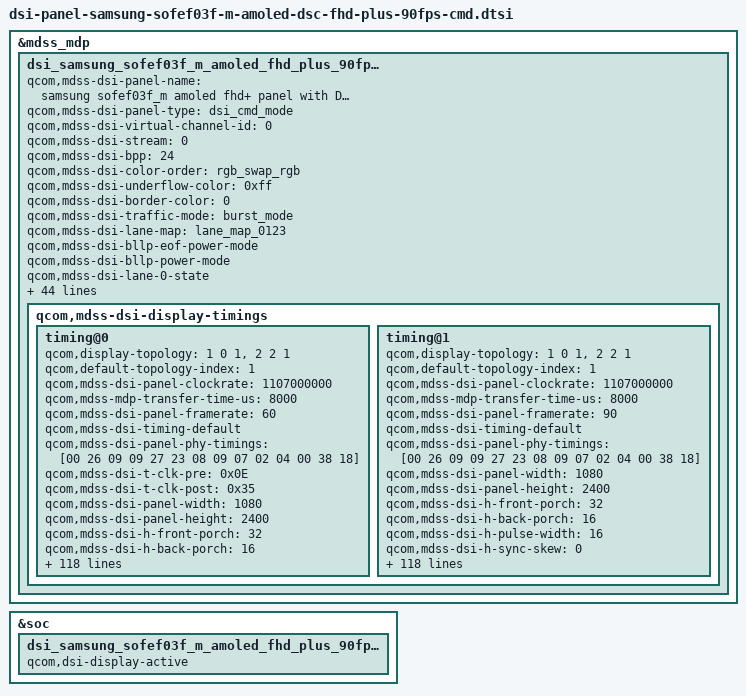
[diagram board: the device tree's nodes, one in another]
/* Copyright (c) 2018, The Linux Foundation. All rights reserved.
 *
 * This program is free software; you can redistribute it and/or modify
 * it under the terms of the GNU General Public License version 2 and
 * only version 2 as published by the Free Software Foundation.
 *
 * This program is distributed in the hope that it will be useful,
 * but WITHOUT ANY WARRANTY; without even the implied warranty of
 * MERCHANTABILITY or FITNESS FOR A PARTICULAR PURPOSE.  See the
 * GNU General Public License for more details.
 */

&mdss_mdp {
	dsi_samsung_sofef03f_m_amoled_fhd_plus_90fps_cmd: qcom,mdss_dsi_samsung_sofef03f_m_fhd_plus_90fps_cmd {
		qcom,mdss-dsi-panel-name =
		  "samsung sofef03f_m amoled fhd+ panel with DSC";
		qcom,mdss-dsi-panel-type = "dsi_cmd_mode";
		qcom,mdss-dsi-virtual-channel-id = <0>;
		qcom,mdss-dsi-stream = <0>;
		qcom,mdss-dsi-bpp = <24>;
		qcom,mdss-dsi-color-order = "rgb_swap_rgb";
		qcom,mdss-dsi-underflow-color = <0xff>;
		qcom,mdss-dsi-border-color = <0>;
		qcom,mdss-dsi-traffic-mode = "burst_mode";
		qcom,mdss-dsi-lane-map = "lane_map_0123";
		qcom,mdss-dsi-bllp-eof-power-mode;
		qcom,mdss-dsi-bllp-power-mode;
		qcom,mdss-dsi-lane-0-state;
		qcom,mdss-dsi-lane-1-state;
		qcom,mdss-dsi-lane-2-state;
		qcom,mdss-dsi-lane-3-state;
		qcom,mdss-dsi-dma-trigger = "trigger_sw";
		qcom,mdss-dsi-mdp-trigger = "trigger_sw";
		qcom,mdss-dsi-reset-sequence = <1 5>, <0 10>, <1 10>;
		//#ifdef OPLUS_BUG_STABILITY
		qcom,mdss-dsi-mode-sel-gpio-state = "single_port";
		oplus,lcd-delay-vci-gpio = <5000>;
		oplus,lcd-delay-disp-en-gpio = <0>;
		oplus,lcd-delay-reset-gpio = <12000>;
		oplus,lcd-delay-mode-sel-gpio = <5000>;
		oplus,lcd-delay-set-pinctrl-state = <1000>;
		oplus,lcd-delay-enable-regulator = <0>;
		oplus,mdss-dsi-vendor-name = "SOFEF03F_M";
		oplus,mdss-dsi-manufacture = "samsung1024";
		//#endif /* OPLUS_BUG_STABILITY */
		qcom,bl-update-flag = "delay_until_first_frame";
		qcom,mdss-dsi-bl-pmic-control-type = "bl_ctrl_dcs";
		qcom,mdss-dsi-bl-min-level = <6>;
		qcom,mdss-dsi-bl-max-level = <2047>;
		qcom,mdss-brightness-default-val = <400>;
		qcom,mdss-brightness-max-level = <2047>;
		qcom,mdss-dsi-bl-normal-max-level = <1023>;
		qcom,mdss-brightness-normal-max-level = <1023>;
		qcom,mdss-dsi-te-pin-select = <1>;
		qcom,mdss-dsi-wr-mem-start = <0x2c>;
		qcom,mdss-dsi-wr-mem-continue = <0x3c>;
		qcom,mdss-dsi-te-dcs-command = <1>;
		qcom,mdss-pan-physical-width-dimension = <68>;
		qcom,mdss-pan-physical-height-dimension = <152>;
		qcom,dynamic-mode-switch-enabled;
		qcom,dynamic-mode-switch-type = "dynamic-switch-immediate";
		qcom,mdss-dsi-panel-hdr-enabled;
		qcom,mdss-dsi-panel-hdr-color-primaries = <15000 15500 34000
			16000 13250 34500 7500 3000>;
		qcom,mdss-dsi-panel-peak-brightness = <4300000>;
		qcom,mdss-dsi-panel-blackness-level = <1023>;
		oplus,dsi-dc-brightness = <0 0xff>,
					<1 0xfb>,
					<2 0xfb>,
					<3 0xfb>,
					<4 0xfa>,
					<5 0xf9>,
					<6 0xf7>,
					<8 0xf5>,
					<10 0xf3>,
					<15 0xf0>,
					<20 0xea>,
					<30 0xe0>,
					<45 0xd0>,
					<70 0xbc>,
					<100 0x98>,
					<120 0x80>,
					<140 0x70>,
					<160 0x58>,
					<180 0x48>,
					<200 0x30>,
					<220 0x20>,
					<240 0x10>,
					<260 0x00>;

		qcom,mdss-dsi-display-timings {
			timing@0{
				qcom,display-topology = <1 0 1>, <2 2 1>;
				qcom,default-topology-index = <1>;
				qcom,mdss-dsi-panel-clockrate = <1107000000>;
				qcom,mdss-mdp-transfer-time-us = <8000>; //for 60fps
				qcom,mdss-dsi-panel-framerate = <60>;
				qcom,mdss-dsi-timing-default;
				qcom,mdss-dsi-panel-phy-timings = [00 26 09 09 27 23 08 09 07 02 04 00 38 18];
				qcom,mdss-dsi-t-clk-pre = <0x0E>;
				qcom,mdss-dsi-t-clk-post = <0x35>;
				qcom,mdss-dsi-panel-width = <1080>;
				qcom,mdss-dsi-panel-height = <2400>;
				qcom,mdss-dsi-h-front-porch = <32>;
				qcom,mdss-dsi-h-back-porch = <16>;
				qcom,mdss-dsi-h-pulse-width = <16>;
				qcom,mdss-dsi-h-sync-skew = <0>;
				qcom,mdss-dsi-h-sync-pulse = <0>;
				qcom,mdss-dsi-v-back-porch = <12>;
				qcom,mdss-dsi-v-front-porch = <12>;
				qcom,mdss-dsi-v-pulse-width = <4>;
				qcom,mdss-dsi-h-left-border = <0>;
				qcom,mdss-dsi-h-right-border = <0>;
				qcom,mdss-dsi-v-top-border = <0>;
				qcom,mdss-dsi-v-bottom-border = <0>;
				qcom,mdss-dsi-panel-jitter = <0x4 0x1>;
				qcom,esd-check-enabled;
				qcom,mdss-dsi-panel-status-check-mode = "reg_read";
				qcom,mdss-dsi-panel-status-command = [06 01 00 01 05 00 02 0A 00];
				qcom,mdss-dsi-panel-status-command-state = "dsi_hs_mode";
				qcom,mdss-dsi-panel-status-value = <0x9C>;
				qcom,mdss-dsi-panel-status-read-length = <1>;
				oplus,fod-on-vblank = <2>;
				oplus,fod-off-vblank = <0>;

				qcom,mdss-dsi-timing-switch-command = [
					/* 60hz Transition */
					39 01 00 00 00 00 03 F0 5A 5A
					15 01 00 00 00 00 02 60 00				/* 0x00 : 60 Hz */
					39 01 00 00 00 00 03 F0 A5 A5
				];
				qcom,mdss-dsi-panel-read-register-open-command = [
					39 01 00 00 00 00 03 F0 5A 5A
				];
				qcom,mdss-dsi-panel-id1-command = [
					06 01 00 00 00 00 02 0A 00
				];
				qcom,mdss-dsi-panel-id2-command = [
					06 01 00 00 00 00 02 B6 00
				];
				qcom,mdss-dsi-panel-read-register-close-command = [
					39 01 00 00 00 00 03 F0 A5 A5
				];
				qcom,mdss-dsi-on-command = [
					/* DSC Setting */
					15 01 00 00 00 00 02 9D 01
					39 01 00 00 00 00 81 9E
					11 00 00 89 30 80 09 60
					04 38 00 1E 02 1C 02 1C
					02 00 02 0E 00 20 02 E3
					00 07 00 0C 03 50 03 64
					18 00 10 F0 03 0C 20 00
					06 0B 0B 33 0E 1C 2A 38
					46 54 62 69 70 77 79 7B
					7D 7E 01 02 01 00 09 40
					09 BE 19 FC 19 FA 19 F8
					1A 38 1A 78 1A B6 2A F6
					2B 34 2B 74 3B 74 6B F4
					00 00 00 00 00 00 00 00
					00 00 00 00 00 00 00 00
					00 00 00 00 00 00 00 00
					00 00 00 00 00 00 00 00
					00 00 00 00 00 00 00 00
					/* Sleep Out(11h) */
					05 01 00 00 0A 00 01 11
					/* Common Setting */
					39 01 00 00 0A 00 03 F0 5A 5A
					15 01 00 00 00 00 02 35 00				/* TE Vsync On */
					39 01 00 00 00 00 03 F0 A5 A5
					/* PAGE ADDRESS SET */
					39 01 00 00 00 00 05 2A 00 00 04 37     /* Page Address Set */
					39 01 00 00 00 00 05 2B 00 00 09 5F		/* Page Address Set */
					/* ELVSS Dim Setting */
					39 01 00 00 00 00 03 F0 5A 5A
					15 01 00 00 00 00 02 B0 05
					15 01 00 00 00 00 02 B7 13				/* 0x13 : ELVSS DIM OFF */
					39 01 00 00 00 00 03 F0 A5 A5
					/* Dimming Delay control */
					39 01 00 00 00 00 03 F0 5A 5A
					15 01 00 00 00 00 02 B0 01
					15 01 00 00 00 00 02 B7 5B				/* 0x53 : DLY OFF */
					39 01 00 00 00 00 03 F0 A5 A5
					/* Dimming Speed Control */
					39 01 00 00 00 00 03 F0 5A 5A
					15 01 00 00 00 00 02 B0 06
					15 01 00 00 00 00 02 B7 01				/* 0x01 : 1 Frames */
					39 01 00 00 00 00 03 F0 A5 A5
					/* FD Setting */
					39 01 00 00 00 00 03 F0 5A 5A
					15 01 00 00 00 00 02 B0 0A
					15 01 00 00 00 00 02 D5 05
					39 01 00 00 00 00 03 F0 A5 A5
					/*  ERR_FG Setting */
					39 01 00 00 00 00 03 F0 5A 5A
					39 01 00 00 00 00 02 B0 02
					39 01 00 00 00 00 05 EC 00 C2 C2 42
					39 01 00 00 00 00 02 B0 0D
					39 01 00 00 00 00 02 EC 19
					39 01 00 00 00 00 03 F0 A5 A5
					/*  Frame Freq Setting +0.5HZ */
					39 01 00 00 00 00 03 FC 5A 5A
					39 01 00 00 00 00 03 F0 5A 5A
					39 01 00 00 00 00 02 B0 17
					39 01 00 00 00 00 02 D1 5D
					39 01 00 00 00 00 02 B0 2A
					39 01 00 00 00 00 06 D3 29 00 00 0D 29
					39 01 00 00 00 00 02 B0 78
					39 01 00 00 00 00 06 D3 4F 00 00 06 4F
					39 01 00 00 00 00 02 B0 AF
					39 01 00 00 00 00 06 D3 29 00 00 0D 29
					39 01 00 00 00 00 02 F7 03
					39 01 00 00 00 00 02 B0 04
					39 01 00 00 00 00 02 D9 72
					39 01 00 00 00 00 03 F0 A5 A5
					39 01 00 00 00 00 03 FC A5 A5
					/* Brightness Control */
					15 01 00 00 00 00 02 53 20				/* 0x20 Normal transition */
					/* ACL Control */
					15 01 00 00 00 00 02 55 00				/* 0x00 Acl off */
					39 01 00 00 00 00 03 51 00 00
					/* 60hz Transition */
					39 01 00 00 00 00 03 F0 5A 5A
					15 01 00 00 00 00 02 60 00				/* 0x00 : 60 Hz */
					39 01 00 00 46 00 03 F0 A5 A5
					/* Display On */
					//05 01 00 00 00 00 01 29
				];
				qcom,mdss-113mhz-osc-dsi-on-command = [
					39 01 00 00 00 00 03 FC 5A 5A
					15 01 00 00 00 00 02 B0 01
					39 01 00 00 00 00 04 E4 A6 75 A3
					39 01 00 00 00 00 0F E9 11 75 A6 75 A3 C7 FB F0 C7 FB F0 00 32 32
					39 01 00 00 00 00 03 FC A5 A5
				];
				qcom,mdss-dsi-post-on-backlight = [
					05 01 00 00 14 00 01 29];
				qcom,mdss-dsi-timing-switch-command-state = "dsi_hs_mode";
				qcom,mdss-113mhz-osc-dsi-on-command-state = "dsi_lp_mode";
				qcom,mdss-dsi-off-command = [
					05 01 00 00 14 00 01 29
					05 01 00 00 16 00 02 28 00
					05 01 00 00 78 00 02 10 00
				];
				qcom,mdss-dsi-lp1-command = [    /* AOD ON */
					05 01 00 00 14 00 01 28
					/* AOD ON */
					39 01 00 00 00 00 03 F0 5A 5A
					15 01 00 00 00 00 02 B0 0A
					15 01 00 00 00 00 02 D5 06
					15 01 00 00 00 00 02 EE 80
					15 01 00 00 11 00 02 60 00
					15 01 00 00 00 00 02 53 23
					39 01 00 00 00 00 03 F0 A5 A5
					/* Seed CRC mode enable */
					39 01 00 00 12 00 02 81 92
					39 01 00 00 00 00 03 F0 5A 5A
					39 01 00 00 00 00 02 B0 2B
					39 01 00 00 00 00 16 B1 CA 00 00 14 D6 00 0E 09 F0 28 FC E0 F8 09 E5 F0 EE 01 FF FF FF  /* CRC LUT2(DCI-P3) */
					39 01 00 00 00 00 02 B1 00
					39 01 00 00 00 00 03 F0 A5 A5
					/* Seed Tcs On */
					39 01 00 00 00 00 03 F0 5A 5A
					39 01 00 00 00 00 02 B0 67
					39 01 00 00 00 00 02 B3 82
					39 01 00 00 00 00 02 83 00
					39 01 00 00 00 00 02 B2 80
					39 01 00 00 3C 00 03 F0 A5 A5
					];
				qcom,mdss-dsi-nolp-command = [    /* AOD OFF */
					/* DSC Setting */
					15 01 00 00 00 00 02 9D 01
					39 01 00 00 00 00 81 9E
					11 00 00 89 30 80 09 60
					04 38 00 1E 02 1C 02 1C
					02 00 02 0E 00 20 02 E3
					00 07 00 0C 03 50 03 64
					18 00 10 F0 03 0C 20 00
					06 0B 0B 33 0E 1C 2A 38
					46 54 62 69 70 77 79 7B
					7D 7E 01 02 01 00 09 40
					09 BE 19 FC 19 FA 19 F8
					1A 38 1A 78 1A B6 2A F6
					2B 34 2B 74 3B 74 6B F4
					00 00 00 00 00 00 00 00
					00 00 00 00 00 00 00 00
					00 00 00 00 00 00 00 00
					00 00 00 00 00 00 00 00
					00 00 00 00 00 00 00 00
					/* Common Setting */
					39 01 00 00 00 00 03 F0 5A 5A
					15 01 00 00 00 00 02 35 00				/* TE Vsync On */
					39 01 00 00 00 00 03 F0 A5 A5
					/* PAGE ADDRESS SET */
					39 01 00 00 00 00 05 2A 00 00 04 37     /* Page Address Set */
					39 01 00 00 00 00 05 2B 00 00 09 5F		/* Page Address Set */
					/* ELVSS Dim Setting */
					39 01 00 00 00 00 03 F0 5A 5A
					15 01 00 00 00 00 02 B0 05
					15 01 00 00 00 00 02 B7 13				/* 0x13 : ELVSS DIM OFF */
					39 01 00 00 00 00 03 F0 A5 A5
					/* Dimming Delay control */
					39 01 00 00 00 00 03 F0 5A 5A
					15 01 00 00 00 00 02 B0 01
					15 01 00 00 00 00 02 B7 5B				/* 0x5B : DLY OFF */
					39 01 00 00 00 00 03 F0 A5 A5
					/* Dimming Speed Control */
					39 01 00 00 00 00 03 F0 5A 5A
					15 01 00 00 00 00 02 B0 06
					15 01 00 00 00 00 02 B7 01				/* 0x01 : 1 Frames */
					39 01 00 00 00 00 03 F0 A5 A5
					/*  ERR_FG Setting */
					39 01 00 00 00 00 03 F0 5A 5A
					39 01 00 00 00 00 02 B0 02
					39 01 00 00 00 00 05 EC 00 C2 C2 42
					39 01 00 00 00 00 02 B0 0D
					39 01 00 00 00 00 02 EC 19
					39 01 00 00 00 00 03 F0 A5 A5
					/*  Frame Freq Setting +0.5HZ */
					39 01 00 00 00 00 03 FC 5A 5A
					39 01 00 00 00 00 03 F0 5A 5A
					39 01 00 00 00 00 02 B0 17
					39 01 00 00 00 00 02 D1 5D
					39 01 00 00 00 00 02 B0 2A
					39 01 00 00 00 00 06 D3 29 00 00 0D 29
					39 01 00 00 00 00 02 B0 78
					39 01 00 00 00 00 06 D3 4F 00 00 06 4F
					39 01 00 00 00 00 02 B0 AF
					39 01 00 00 00 00 06 D3 29 00 00 0D 29
					39 01 00 00 00 00 02 F7 03
					39 01 00 00 00 00 02 B0 04
					39 01 00 00 00 00 02 D9 72
					39 01 00 00 00 00 03 F0 A5 A5
					39 01 00 00 00 00 03 FC A5 A5
					/* ACL Control */
					15 01 00 00 00 00 02 55 00				/* 0x00 Acl off */
					/* AOD OFF */
					39 01 00 00 00 00 03 F0 5A 5A
					15 01 00 00 00 00 02 B0 0A
					15 01 00 00 00 00 02 D5 05
					15 01 00 00 00 00 02 60 00				/* 0x00 : 60 Hz */
					15 01 00 00 00 00 02 53 20
					39 01 00 00 00 00 03 F0 A5 A5
					/** HBM backlight off ***/
					39 01 00 00 00 00 03 F0 5A 5A
					39 01 00 00 00 00 02 B0 BB
					39 01 00 00 00 00 02 BA F7
					39 01 00 00 00 00 02 B0 01
					39 01 00 00 00 00 03 B7 52 A8
					39 01 00 00 00 00 02 B0 0A
					39 01 00 00 00 00 11 B7 00 00 00 00 21 41 41 41 62 02 62 82 83 43 A3 03
					39 01 00 00 00 00 02 B0 3C
					39 01 00 00 00 00 1B B7 2E 23 2F 37 C3 C9 41 64 63 4B 04 FD 54 A5 97 5E 46 31 67 E6 CB 71 87 65 7B 20
					39 01 00 00 00 00 03 F0 A5 A5
					/* Display On */
					05 01 00 00 00 00 01 29
					];
				qcom,mdss-dsi-aod-hbm-on-command = [  /*AOD->HBM ON PANEL FINGERPRINT OFF*/
					/* ELVSS Dim Setting */
					39 01 00 00 00 00 03 F0 5A 5A
					15 01 00 00 00 00 02 B0 05
					15 01 00 00 00 00 02 B7 13				/* 0x93 : ELVSS DIM OFF */
					39 01 00 00 00 00 03 F0 A5 A5
					/* Dimming Delay control */
					39 01 00 00 00 00 03 F0 5A 5A
					15 01 00 00 00 00 02 B0 01
					15 01 00 00 00 00 02 B7 5B				/* 0x5B : DLY OFF */
					39 01 00 00 05 00 03 F0 A5 A5
					/* HBM Mode ON */
					39 01 00 00 00 00 02 53 E0
					/* 0xE0 Normal transition */
					39 01 00 00 00 00 03 51 03 FF                /* 700nit */
					/* Dimming Delay control */
					39 01 00 00 00 00 03 F0 5A 5A
					39 01 00 00 00 00 02 B0 01
					39 01 00 00 00 00 02 B7 53
					/* 0x53 : DLY ON */
					39 01 00 00 00 00 03 F0 A5 A5
					];
				qcom,mdss-dsi-aod-hbm-off-command = [  /*AOD->HBM OFF PANEL FINGERPRINT OFF*/
					15 01 00 00 00 00 02 53 22
					];
				qcom,mdss-dsi-hbm-on-command = [
					15 01 00 00 00 00 02 53 E0
					39 01 00 00 00 00 03 51 03 FF];
				qcom,mdss-dsi-hbm-off-command = [
					15 01 00 00 00 00 02 53 20
					39 01 00 00 00 00 03 F0 5A 5A
					39 01 00 00 00 00 02 B0 BB
					39 01 00 00 00 00 02 BA F7
					39 01 00 00 00 00 02 B0 01
					39 01 00 00 00 00 03 B7 52 A8
					39 01 00 00 00 00 02 B0 0A
					39 01 00 00 00 00 11 B7 00 00 00 00 21 41 41 41 62 02 62 82 83 43 A3 03
					39 01 00 00 00 00 02 B0 3C
					39 01 00 00 00 00 1B B7 2E 23 2F 37 C3 C9 41 64 63 4B 04 FD 54 A5 97 5E 46 31 67 E6 CB 71 87 65 7B 20
					39 01 00 00 00 00 03 F0 A5 A5];
				qcom,mdss-dsi-hbm-backlight-on-command = [
					39 01 00 00 00 00 03 F0 5A 5A
					39 01 00 00 00 00 02 B0 BB
					39 01 00 00 00 00 02 BA 77
					39 01 00 00 00 00 02 B0 01
					39 01 00 00 00 00 03 B7 57 FF
					39 01 00 00 00 00 02 B0 0A
					39 01 00 00 00 00 11 B7 00 01 02 03 24 45 46 47 68 09 6A 8B 8C 40 A1 02
					39 01 00 00 00 00 02 B0 3C
					39 01 00 00 00 00 1B B7 41 65 4A 67 E7 FF 80 08 55 8A A9 54 9F EA A8 B5 2B FC CA 6D 50 DF AE A4 F4 E0
					39 01 00 00 0A 00 03 F0 A5 A5];
				qcom,mdss-dsi-hbm-backlight-off-command = [
					39 01 00 00 00 00 03 F0 5A 5A
					39 01 00 00 00 00 02 B0 BB
					39 01 00 00 00 00 02 BA F7
					39 01 00 00 00 00 02 B0 01
					39 01 00 00 00 00 03 B7 52 A8
					39 01 00 00 00 00 02 B0 0A
					39 01 00 00 00 00 11 B7 00 00 00 00 21 41 41 41 62 02 62 82 83 43 A3 03
					39 01 00 00 00 00 02 B0 3C
					39 01 00 00 00 00 1B B7 2E 23 2F 37 C3 C9 41 64 63 4B 04 FD 54 A5 97 5E 46 31 67 E6 CB 71 87 65 7B 20
					39 01 00 00 00 00 03 F0 A5 A5];
				qcom,mdss-dsi-normal-hbm-on-command = [
					15 01 00 00 00 00 02 53 E0
					39 01 00 00 00 00 03 51 03 FF];
				qcom,mdss-dsi-aod-high-mode-command = [
					/* AOD 50nit */
					15 01 00 00 00 00 02 53 22];
				qcom,mdss-dsi-aod-low-mode-command = [
					/* AOD 10nit */
					15 01 00 00 00 00 02 53 23];
				qcom,mdss-dsi-seed-off-command = [
					39 01 00 00 00 00 03 F0 5A 5A
					39 01 00 00 00 00 03 B1 00 01  /* SEED CRC OFF */
					39 01 00 00 00 00 03 F0 A5 A5
					39 01 00 00 00 00 03 F0 5A 5A
					39 01 00 00 00 00 02 B2 81     /* SEED TCS OFF */
					39 01 00 00 00 00 03 F0 A5 A5
				];
				qcom,mdss-dsi-seed-0-command = [
					39 01 00 00 00 00 02 81 92
					39 01 00 00 00 00 03 F0 5A 5A
					39 01 00 00 00 00 02 B0 2B
					39 01 00 00 00 00 16 B1 CA 00 00 14 D6 00 0E 09 F0 28 FC E0 F8 09 E5 F0 EE 01 FF FF FF  /* CRC LUT2(DCI-P3) */
					39 01 00 00 00 00 02 B1 00
					39 01 00 00 00 00 03 F0 A5 A5
					/* Seed Tcs On */
					39 01 00 00 00 00 03 F0 5A 5A
					39 01 00 00 00 00 02 B0 67
					39 01 00 00 00 00 02 B3 82
					39 01 00 00 00 00 02 83 00
					39 01 00 00 00 00 02 B2 80
					39 01 00 00 00 00 03 F0 A5 A5
				];
				qcom,mdss-dsi-seed-1-command = [
					39 01 00 00 00 00 02 81 90
					39 01 00 00 00 00 03 F0 5A 5A
					39 01 00 00 00 00 02 B0 01
					39 01 00 00 00 00 16 B1 A8 0A 05 41 D0 14 0A 06 AF 56 EE D5 BE 13 BD E6 E4 1C FF FF FF  /* CRC LUT1(sRGB) */
					39 01 00 00 00 00 02 B1 00
					39 01 00 00 00 00 03 F0 A5 A5
					/* Seed Tcs On */
					39 01 00 00 00 00 03 F0 5A 5A
					39 01 00 00 00 00 02 B0 67
					39 01 00 00 00 00 02 B3 82
					39 01 00 00 00 00 02 83 00
					39 01 00 00 00 00 02 B2 80
					39 01 00 00 00 00 03 F0 A5 A5
				];
				qcom,mdss-dsi-seed-dcip3-command = [
					39 01 00 00 00 00 02 81 92
					39 01 00 00 00 00 03 F0 5A 5A
					39 01 00 00 00 00 02 B0 2B
					39 01 00 00 00 00 16 B1 CA 00 00 14 D6 00 0E 09 F0 28 FC E0 F8 09 E5 F0 EE 01 FF FF FF  /* CRC LUT2(DCI-P3) */
					39 01 00 00 00 00 02 B1 00
					39 01 00 00 00 00 03 F0 A5 A5
					/* Seed Tcs On */
					39 01 00 00 00 00 03 F0 5A 5A
					39 01 00 00 00 00 02 B0 67
					39 01 00 00 00 00 02 B3 82
					39 01 00 00 00 00 02 83 00
					39 01 00 00 00 00 02 B2 80
					39 01 00 00 00 00 03 F0 A5 A5
				];
				qcom,mdss-dsi-hdr10-seed-command = [
					/* Seed CRC mode enable */
					39 01 00 00 00 00 02 81 92
					39 01 00 00 00 00 03 F0 5A 5A
					39 01 00 00 00 00 02 B0 2B
					39 01 00 00 00 00 16 B1 FF 00 00 00 FF 00 00 00 FF 00 FF FF FF 00 FF FF FF 00 FF FF FF  /* CRC LUT2(DCI-P3) */
					39 01 00 00 00 00 02 B1 00
					39 01 00 00 00 00 03 F0 A5 A5
					/* Seed Tcs On */
					39 01 00 00 00 00 03 F0 5A 5A
					39 01 00 00 00 00 02 B0 67
					39 01 00 00 00 00 02 B3 82
					39 01 00 00 00 00 02 83 00
					39 01 00 00 00 00 02 B2 80
					39 01 00 00 00 00 03 F0 A5 A5
				];
				qcom,mdss-dsi-on-command-state = "dsi_lp_mode";
				qcom,mdss-dsi-off-command-state = "dsi_lp_mode";
				qcom,mdss-dsi-lp1-command-state = "dsi_hs_mode";
				qcom,mdss-dsi-nolp-command-state = "dsi_hs_mode";
				qcom,mdss-dsi-post-on-backlight-state = "dsi_hs_mode";
				qcom,mdss-dsi-seed-dcip3-command-state = "dsi_hs_mode";
				qcom,mdss-dsi-seed-srgb-command-state = "dsi_hs_mode";
				qcom,mdss-dsi-seed-off-command-state = "dsi_hs_mode";
				qcom,mdss-dsi-normal-hbm-on-command-state = "dsi_hs_mode";
				qcom,mdss-dsi-aod-high-mode-command-state = "dsi_hs_mode";
				qcom,mdss-dsi-aod-low-mode-command-state = "dsi_hs_mode";
				qcom,mdss-dsi-hbm-backlight-on-command-state = "dsi_hs_mode";
				qcom,mdss-dsi-hbm-backlight-off-command-state = "dsi_hs_mode";
				qcom,mdss-dsi-panel-read-register-open-command-state  = "dsi_lp_mode";
				qcom,mdss-dsi-panel-id1-command-state = "dsi_lp_mode";
				qcom,mdss-dsi-panel-id2-command-state = "dsi_lp_mode";
				qcom,mdss-dsi-panel-read-register-close-command-state = "dsi_lp_mode";
				qcom,mdss-dsi-hdr10-seed-command-state =  "dsi_lp_mode";
				qcom,panel-roi-alignment=<540 30 540 30 540 30>;
				qcom,compression-mode = "dsc";
				qcom,lm-split = <540 540>;
				qcom,mdss-dsc-encoders = <2>;
				qcom,mdss-dsc-slice-height = <30>;
				qcom,mdss-dsc-slice-width = <540>;
				qcom,mdss-dsc-slice-per-pkt = <2>;
				qcom,mdss-dsc-bit-per-component = <8>;
				qcom,mdss-dsc-bit-per-pixel = <8>;
				qcom,mdss-dsc-block-prediction-enable;
			};

			timing@1{
				qcom,display-topology = <1 0 1>, <2 2 1>;
				qcom,default-topology-index = <1>;
				qcom,mdss-dsi-panel-clockrate = <1107000000>;
				qcom,mdss-mdp-transfer-time-us = <8000>; //for 60fps
				qcom,mdss-dsi-panel-framerate = <90>;
				qcom,mdss-dsi-timing-default;
				qcom,mdss-dsi-panel-phy-timings = [00 26 09 09 27 23 08 09 07 02 04 00 38 18];
				qcom,mdss-dsi-panel-width = <1080>;
				qcom,mdss-dsi-panel-height = <2400>;
				qcom,mdss-dsi-h-front-porch = <32>;
				qcom,mdss-dsi-h-back-porch = <16>;
				qcom,mdss-dsi-h-pulse-width = <16>;
				qcom,mdss-dsi-h-sync-skew = <0>;
				qcom,mdss-dsi-h-sync-pulse = <0>;
				qcom,mdss-dsi-v-back-porch = <12>;
				qcom,mdss-dsi-v-front-porch = <4>;
				qcom,mdss-dsi-v-pulse-width = <4>;
				qcom,mdss-dsi-h-left-border = <0>;
				qcom,mdss-dsi-h-right-border = <0>;
				qcom,mdss-dsi-v-top-border = <0>;
				qcom,mdss-dsi-v-bottom-border = <0>;
				qcom,mdss-dsi-panel-jitter = <0x4 0x1>;
				qcom,esd-check-enabled;
				qcom,mdss-dsi-panel-status-check-mode = "reg_read";
				qcom,mdss-dsi-panel-status-command = [06 01 00 01 05 00 02 0A 00];
				qcom,mdss-dsi-panel-status-command-state = "dsi_hs_mode";
				qcom,mdss-dsi-panel-status-value = <0x9C>;
				qcom,mdss-dsi-panel-status-read-length = <1>;
				oplus,fod-on-vblank = <2>;
				oplus,fod-off-vblank = <0>;
				qcom,mdss-dsi-timing-switch-command = [
					39 01 00 00 00 00 03 F0 5A 5A           /* Dimming Setting */
					15 01 00 00 00 00 02 60 10              /* 0x10 Normal transition(90Hz) */
					39 01 00 00 00 00 03 F0 A5 A5
				];
				 qcom,mdss-dsi-panel-read-register-open-command = [
					39 01 00 00 00 00 03 F0 5A 5A
				];
				qcom,mdss-dsi-panel-id1-command = [
					06 01 00 00 00 00 02 0A 00
				];
				qcom,mdss-dsi-panel-id2-command = [
					06 01 00 00 00 00 02 B6 00
				];
				qcom,mdss-dsi-panel-read-register-close-command = [
					39 01 00 00 00 00 03 F0 A5 A5
				];
				qcom,mdss-dsi-t-clk-pre = <0x0E>;
				qcom,mdss-dsi-t-clk-post = <0x35>;
				qcom,mdss-dsi-on-command = [
					/* DSC Setting */
					15 01 00 00 00 00 02 9D 01
					39 01 00 00 00 00 81 9E
					11 00 00 89 30 80 09 60
					04 38 00 1E 02 1C 02 1C
					02 00 02 0E 00 20 02 E3
					00 07 00 0C 03 50 03 64
					18 00 10 F0 03 0C 20 00
					06 0B 0B 33 0E 1C 2A 38
					46 54 62 69 70 77 79 7B
					7D 7E 01 02 01 00 09 40
					09 BE 19 FC 19 FA 19 F8
					1A 38 1A 78 1A B6 2A F6
					2B 34 2B 74 3B 74 6B F4
					00 00 00 00 00 00 00 00
					00 00 00 00 00 00 00 00
					00 00 00 00 00 00 00 00
					00 00 00 00 00 00 00 00
					00 00 00 00 00 00 00 00
					/* Sleep Out(11h) */
					05 01 00 00 0A 00 01 11
					/* Common Setting */
					39 01 00 00 0A 00 03 F0 5A 5A
					15 01 00 00 00 00 02 35 00				/* TE Vsync On */
					39 01 00 00 00 00 03 F0 A5 A5
					/* PAGE ADDRESS SET */
					39 01 00 00 00 00 05 2A 00 00 04 37		/* Page Address Set */
					39 01 00 00 00 00 05 2B 00 00 09 5F		/* Page Address Set */
					/* ELVSS Dim Setting */
					39 01 00 00 00 00 03 F0 5A 5A
					15 01 00 00 00 00 02 B0 05
					15 01 00 00 00 00 02 B7 13				/* 0x13 : ELVSS DIM OFF */
					39 01 00 00 00 00 03 F0 A5 A5
					/* Dimming Delay control */
					39 01 00 00 00 00 03 F0 5A 5A
					15 01 00 00 00 00 02 B0 01
					15 01 00 00 00 00 02 B7 53				/* 0x5B : DLY ON */
					39 01 00 00 00 00 03 F0 A5 A5
					/* Dimming Speed Control */
					39 01 00 00 00 00 03 F0 5A 5A
					15 01 00 00 00 00 02 B0 06
					15 01 00 00 00 00 02 B7 01				/* 0x01 : 1 Frames */
					39 01 00 00 00 00 03 F0 A5 A5
					/* FD Setting */
					39 01 00 00 00 00 03 F0 5A 5A
					15 01 00 00 00 00 02 B0 0A
					15 01 00 00 00 00 02 D5 05
					39 01 00 00 00 00 03 F0 A5 A5
					/*  ERR_FG Setting */
					39 01 00 00 00 00 03 F0 5A 5A
					39 01 00 00 00 00 02 B0 02
					39 01 00 00 00 00 05 EC 00 C2 C2 42
					39 01 00 00 00 00 02 B0 0D
					39 01 00 00 00 00 02 EC 19
					39 01 00 00 00 00 03 F0 A5 A5
					/*  Frame Freq Setting +0.5HZ */
					39 01 00 00 00 00 03 FC 5A 5A
					39 01 00 00 00 00 03 F0 5A 5A
					39 01 00 00 00 00 02 B0 17
					39 01 00 00 00 00 02 D1 5D
					39 01 00 00 00 00 02 B0 2A
					39 01 00 00 00 00 06 D3 29 00 00 0D 29
					39 01 00 00 00 00 02 B0 78
					39 01 00 00 00 00 06 D3 4F 00 00 06 4F
					39 01 00 00 00 00 02 B0 AF
					39 01 00 00 00 00 06 D3 29 00 00 0D 29
					39 01 00 00 00 00 02 F7 03
					39 01 00 00 00 00 02 B0 04
					39 01 00 00 00 00 02 D9 72
					39 01 00 00 00 00 03 F0 A5 A5
					39 01 00 00 00 00 03 FC A5 A5
					/* Brightness Control */
					15 01 00 00 00 00 02 53 20				/* 0x20 Normal transition */
					/* ACL Control */
					15 01 00 00 00 00 02 55 00				/* 0x00 Acl off */
					39 01 00 00 00 00 03 51 00 00
					/* 60hz Transition */
					39 01 00 00 00 00 03 F0 5A 5A
					15 01 00 00 00 00 02 60 10				/* 0x10 : 90 Hz */
					39 01 00 00 46 00 03 F0 A5 A5
					/* Display On */
					//05 01 00 00 00 00 01 29
				];
				qcom,mdss-113mhz-osc-dsi-on-command = [
					39 01 00 00 00 00 03 FC 5A 5A
					15 01 00 00 00 00 02 B0 01
					39 01 00 00 00 00 04 E4 A6 75 A3
					39 01 00 00 00 00 0F E9 11 75 A6 75 A3 C7 FB F0 C7 FB F0 00 32 32
					39 01 00 00 00 00 03 FC A5 A5
				];
				qcom,mdss-dsi-post-on-backlight = [
					05 01 00 00 14 00 01 29];
				qcom,mdss-dsi-off-command = [
					05 01 00 00 14 00 01 29
					05 01 00 00 16 00 02 28 00
					05 01 00 00 78 00 02 10 00
				];
				qcom,mdss-dsi-lp1-command = [    /* AOD ON */
					05 01 00 00 14 00 01 28
					/* AOD ON */
					39 01 00 00 00 00 03 F0 5A 5A
					15 01 00 00 00 00 02 B0 0A
					15 01 00 00 00 00 02 D5 06
					15 01 00 00 00 00 02 EE 80
					15 01 00 00 11 00 02 60 00
					15 01 00 00 00 00 02 53 23
					39 01 00 00 00 00 03 F0 A5 A5
					/* Seed CRC mode enable */
					39 01 00 00 12 00 02 81 92
					39 01 00 00 00 00 03 F0 5A 5A
					39 01 00 00 00 00 02 B0 2B
					39 01 00 00 00 00 16 B1 CA 00 00 14 D6 00 0E 09 F0 28 FC E0 F8 09 E5 F0 EE 01 FF FF FF  /* CRC LUT2(DCI-P3) */
					39 01 00 00 00 00 02 B1 00
					39 01 00 00 00 00 03 F0 A5 A5
					/* Seed Tcs On */
					39 01 00 00 00 00 03 F0 5A 5A
					39 01 00 00 00 00 02 B0 67
					39 01 00 00 00 00 02 B3 82
					39 01 00 00 00 00 02 83 00
					39 01 00 00 00 00 02 B2 80
					39 01 00 00 3C 00 03 F0 A5 A5
					];
				qcom,mdss-dsi-nolp-command = [    /* AOD OFF */
					/* DSC Setting */
					15 01 00 00 00 00 02 9D 01
					39 01 00 00 00 00 81 9E
					11 00 00 89 30 80 09 60
					04 38 00 1E 02 1C 02 1C
					02 00 02 0E 00 20 02 E3
					00 07 00 0C 03 50 03 64
					18 00 10 F0 03 0C 20 00
					06 0B 0B 33 0E 1C 2A 38
					46 54 62 69 70 77 79 7B
					7D 7E 01 02 01 00 09 40
					09 BE 19 FC 19 FA 19 F8
					1A 38 1A 78 1A B6 2A F6
					2B 34 2B 74 3B 74 6B F4
					00 00 00 00 00 00 00 00
					00 00 00 00 00 00 00 00
					00 00 00 00 00 00 00 00
					00 00 00 00 00 00 00 00
					00 00 00 00 00 00 00 00
					/* AOD OFF */
					39 01 00 00 00 00 03 F0 5A 5A
					15 01 00 00 00 00 02 B0 0A
					15 01 00 00 00 00 02 D5 05
					15 01 00 00 00 00 02 60 10				/* 0x10 : 90 Hz */
					15 01 00 00 00 00 02 53 20				/* 0x20 Normal transition */
					39 01 00 00 00 00 03 F0 A5 A5
					/* Common Setting */
					39 01 00 00 00 00 03 F0 5A 5A
					15 01 00 00 00 00 02 35 00				/* TE Vsync On */
					39 01 00 00 00 00 03 F0 A5 A5
					/* PAGE ADDRESS SET */
					39 01 00 00 00 00 05 2A 00 00 04 37     /* Page Address Set */
					39 01 00 00 00 00 05 2B 00 00 09 5F		/* Page Address Set */
					/* ELVSS Dim Setting */
					39 01 00 00 00 00 03 F0 5A 5A
					15 01 00 00 00 00 02 B0 05
					15 01 00 00 00 00 02 B7 13				/* 0x93 : ELVSS DIM OFF */
					39 01 00 00 00 00 03 F0 A5 A5
					/* Dimming Delay control */
					39 01 00 00 00 00 03 F0 5A 5A
					15 01 00 00 00 00 02 B0 01
					15 01 00 00 08 00 02 B7 5B				/* 0x5B : DLY OFF */
					39 01 00 00 00 00 03 F0 A5 A5
					/* Dimming Speed Control */
					39 01 00 00 00 00 03 F0 5A 5A
					15 01 00 00 00 00 02 B0 06
					15 01 00 00 00 00 02 B7 01				/* 0x01 : 1 Frames */
					39 01 00 00 00 00 03 F0 A5 A5
					/*  ERR_FG Setting */
					39 01 00 00 00 00 03 F0 5A 5A
					39 01 00 00 00 00 02 B0 02
					39 01 00 00 00 00 05 EC 00 C2 C2 42
					39 01 00 00 00 00 02 B0 0D
					39 01 00 00 00 00 02 EC 19
					39 01 00 00 00 00 03 F0 A5 A5
					/*  Frame Freq Setting +0.5HZ */
					39 01 00 00 00 00 03 FC 5A 5A
					39 01 00 00 00 00 03 F0 5A 5A
					39 01 00 00 00 00 02 B0 17
					39 01 00 00 00 00 02 D1 5D
					39 01 00 00 00 00 02 B0 2A
					39 01 00 00 00 00 06 D3 29 00 00 0D 29
					39 01 00 00 00 00 02 B0 78
					39 01 00 00 00 00 06 D3 4F 00 00 06 4F
					39 01 00 00 00 00 02 B0 AF
					39 01 00 00 00 00 06 D3 29 00 00 0D 29
					39 01 00 00 00 00 02 F7 03
					39 01 00 00 00 00 02 B0 04
					39 01 00 00 00 00 02 D9 72
					39 01 00 00 00 00 03 F0 A5 A5
					39 01 00 00 00 00 03 FC A5 A5
					/* ACL Control */
					15 01 00 00 00 00 02 55 00				/* 0x00 Acl off */
					/* Display On */
					05 01 00 00 00 00 01 29
					];
				qcom,mdss-dsi-aod-hbm-on-command = [  /*AOD->HBM ON PANEL FINGERPRINT OFF*/
					/* ELVSS Dim Setting */
					39 01 00 00 00 00 03 F0 5A 5A
					15 01 00 00 00 00 02 B0 05
					15 01 00 00 00 00 02 B7 13				/* 0x93 : ELVSS DIM OFF */
					39 01 00 00 00 00 03 F0 A5 A5
					/* Dimming Delay control */
					39 01 00 00 00 00 03 F0 5A 5A
					15 01 00 00 00 00 02 B0 01
					15 01 00 00 00 00 02 B7 5B				/* 0x5B : DLY OFF */
					39 01 00 00 00 00 03 F0 A5 A5
					/* HBM Mode ON */
					39 01 00 00 00 00 02 53 E0
					/* 0xE0 Normal transition */
					39 01 00 00 00 00 03 51 03 FF                /* 700nit */
					/* Dimming Delay control */
					39 01 00 00 00 00 03 F0 5A 5A
					39 01 00 00 00 00 02 B0 01
					39 01 00 00 00 00 02 B7 53
					/* 0x53 : DLY ON */
					39 01 00 00 00 00 03 F0 A5 A5
					];
				qcom,mdss-dsi-aod-hbm-off-command = [  /*AOD->HBM OFF PANEL FINGERPRINT OFF*/
					15 01 00 00 00 00 02 53 22
					];
				qcom,mdss-dsi-hbm-on-command = [
					15 01 00 00 00 00 02 53 E0
					39 01 00 00 00 00 03 51 03 FF];
				qcom,mdss-dsi-hbm-off-command = [
					15 01 00 00 00 00 02 53 20];
				qcom,mdss-dsi-normal-hbm-on-command = [
					15 01 00 00 00 00 02 53 E0
					39 01 00 00 00 00 03 51 03 FF];
				qcom,mdss-dsi-hbm-backlight-on-command = [
					39 01 00 00 00 00 03 F0 5A 5A
					39 01 00 00 00 00 02 B0 BB
					39 01 00 00 00 00 02 BA 77
					39 01 00 00 00 00 02 B0 01
					39 01 00 00 00 00 03 B7 57 FF
					39 01 00 00 00 00 02 B0 0A
					39 01 00 00 00 00 11 B7 00 01 02 03 24 45 46 47 68 09 6A 8B 8C 40 A1 02
					39 01 00 00 00 00 02 B0 3C
					39 01 00 00 00 00 1B B7 41 65 4A 67 E7 FF 80 08 55 8A A9 54 9F EA A8 B5 2B FC CA 6D 50 DF AE A4 F4 E0
					39 01 00 00 0A 00 03 F0 A5 A5];
				qcom,mdss-dsi-hbm-backlight-off-command = [
					39 01 00 00 00 00 03 F0 5A 5A
					39 01 00 00 00 00 02 B0 BB
					39 01 00 00 00 00 02 BA F7
					39 01 00 00 00 00 02 B0 01
					39 01 00 00 00 00 03 B7 52 A8
					39 01 00 00 00 00 02 B0 0A
					39 01 00 00 00 00 11 B7 00 00 00 00 21 41 41 41 62 02 62 82 83 43 A3 03
					39 01 00 00 00 00 02 B0 3C
					39 01 00 00 00 00 1B B7 2E 23 2F 37 C3 C9 41 64 63 4B 04 FD 54 A5 97 5E 46 31 67 E6 CB 71 87 65 7B 20
					39 01 00 00 00 00 03 F0 A5 A5];
				qcom,mdss-dsi-aod-high-mode-command = [
					/* AOD 50nit */
					15 01 00 00 00 00 02 53 22];
				qcom,mdss-dsi-aod-low-mode-command = [
					/* AOD 10nit */
					15 01 00 00 00 00 02 53 23];
				qcom,mdss-dsi-seed-off-command = [
					39 01 00 00 00 00 03 F0 5A 5A
					39 01 00 00 00 00 03 B1 00 01  /* SEED CRC OFF */
					39 01 00 00 00 00 03 F0 A5 A5
					39 01 00 00 00 00 03 F0 5A 5A
					39 01 00 00 00 00 02 B2 81     /* SEED TCS OFF */
					39 01 00 00 00 00 03 F0 A5 A5
				];
				qcom,mdss-dsi-seed-0-command = [
					/* Seed CRC mode enable */
					39 01 00 00 00 00 02 81 92
					39 01 00 00 00 00 03 F0 5A 5A
					39 01 00 00 00 00 02 B0 2B
					39 01 00 00 00 00 16 B1 CA 00 00 14 D6 00 0E 09 F0 28 FC E0 F8 09 E5 F0 EE 01 FF FF FF  /* CRC LUT2(DCI-P3) */
					39 01 00 00 00 00 02 B1 00
					39 01 00 00 00 00 03 F0 A5 A5
					/* Seed Tcs On */
					39 01 00 00 00 00 03 F0 5A 5A
					39 01 00 00 00 00 02 B0 67
					39 01 00 00 00 00 02 B3 82
					39 01 00 00 00 00 02 83 00
					39 01 00 00 00 00 02 B2 80
					39 01 00 00 00 00 03 F0 A5 A5
				];
				qcom,mdss-dsi-seed-1-command = [					/* Seed CRC mode enable */
					39 00 00 00 00 00 02 81 90
					39 00 00 00 00 00 03 F0 5A 5A
					39 00 00 00 00 00 02 B0 01
					39 00 00 00 00 00 16 B1 A8 0A 05 41 D0 14 0A 06 AF 56 EE D5 BE 13 BD E6 E4 1C FF FF FF  /* CRC LUT1(sRGB) */
					39 00 00 00 00 00 02 B1 00
					39 00 00 00 00 00 03 F0 A5 A5
					/* Seed Tcs On */
					39 00 00 00 00 00 03 F0 5A 5A
					39 00 00 00 00 00 02 B0 67
					39 00 00 00 00 00 02 B3 82
					39 00 00 00 00 00 02 83 00
					39 00 00 00 00 00 02 B2 80
					39 01 00 00 00 00 03 F0 A5 A5
				];
				qcom,mdss-dsi-seed-dcip3-command = [
					39 01 00 00 00 00 02 81 92
					39 01 00 00 00 00 03 F0 5A 5A
					39 01 00 00 00 00 02 B0 2B
					39 01 00 00 00 00 16 B1 CA 00 00 14 D6 00 0E 09 F0 28 FC E0 F8 09 E5 F0 EE 01 FF FF FF  /* CRC LUT2(DCI-P3) */
					39 01 00 00 00 00 02 B1 00
					39 01 00 00 00 00 03 F0 A5 A5
					/* Seed Tcs On */
					39 01 00 00 00 00 03 F0 5A 5A
					39 01 00 00 00 00 02 B0 67
					39 01 00 00 00 00 02 B3 82
					39 01 00 00 00 00 02 83 00
					39 01 00 00 00 00 02 B2 80
					39 01 00 00 00 00 03 F0 A5 A5
				];
				qcom,mdss-dsi-hdr10-seed-command = [
					/* Seed CRC mode enable */
					39 01 00 00 00 00 02 81 92
					39 01 00 00 00 00 03 F0 5A 5A
					39 01 00 00 00 00 02 B0 2B
					39 01 00 00 00 00 16 B1 FF 00 00 00 FF 00 00 00 FF 00 FF FF FF 00 FF FF FF 00 FF FF FF  /* CRC LUT2(DCI-P3) */
					39 01 00 00 00 00 02 B1 00
					39 01 00 00 00 00 03 F0 A5 A5
					/* Seed Tcs On */
					39 01 00 00 00 00 03 F0 5A 5A
					39 01 00 00 00 00 02 B0 67
					39 01 00 00 00 00 02 B3 82
					39 01 00 00 00 00 02 83 00
					39 01 00 00 00 00 02 B2 80
					39 01 00 00 00 00 03 F0 A5 A5
				];
				qcom,mdss-dsi-on-command-state = "dsi_lp_mode";
				qcom,mdss-dsi-off-command-state = "dsi_lp_mode";
				qcom,mdss-dsi-lp1-command-state = "dsi_hs_mode";
				qcom,mdss-dsi-nolp-command-state = "dsi_hs_mode";
				qcom,mdss-dsi-post-on-backlight-state = "dsi_hs_mode";
				qcom,mdss-dsi-seed-dcip3-command-state = "dsi_hs_mode";
				qcom,mdss-dsi-seed-srgb-command-state = "dsi_hs_mode";
				qcom,mdss-dsi-seed-off-command-state = "dsi_hs_mode";
				qcom,mdss-dsi-hbm-backlight-on-command-state = "dsi_hs_mode";
				qcom,mdss-dsi-hbm-backlight-off-command-state = "dsi_hs_mode";
				qcom,mdss-dsi-normal-hbm-on-command-state = "dsi_hs_mode";
				qcom,mdss-dsi-aod-high-mode-command-state = "dsi_hs_mode";
				qcom,mdss-dsi-aod-low-mode-command-state = "dsi_hs_mode";
				qcom,mdss-dsi-timing-switch-command-state = "dsi_hs_mode";
				qcom,mdss-113mhz-osc-dsi-on-command-state = "dsi_lp_mode";
				qcom,mdss-dsi-panel-read-register-open-command-state  = "dsi_lp_mode";
				qcom,mdss-dsi-panel-id1-command-state = "dsi_lp_mode";
				qcom,mdss-dsi-panel-id2-command-state = "dsi_lp_mode";
				qcom,mdss-dsi-panel-read-register-close-command-state = "dsi_lp_mode";
				qcom,mdss-dsi-hdr10-seed-command-state =  "dsi_lp_mode";
				qcom,panel-roi-alignment=<540 30 540 30 540 30>;
				qcom,compression-mode = "dsc";
				qcom,lm-split = <540 540>;
				qcom,mdss-dsc-encoders = <2>;
				qcom,mdss-dsc-slice-height = <30>;
				qcom,mdss-dsc-slice-width = <540>;
				qcom,mdss-dsc-slice-per-pkt = <2>;
				qcom,mdss-dsc-bit-per-component = <8>;
				qcom,mdss-dsc-bit-per-pixel = <8>;
				qcom,mdss-dsc-block-prediction-enable;
			};

		};
	};
};

&soc {
    dsi_samsung_sofef03f_m_amoled_fhd_plus_90fps_cmd {
        qcom,dsi-display-active;
    };
};

&dsi_samsung_sofef03f_m_amoled_fhd_plus_90fps_cmd {
            qcom,mdss-dsi-display-timings {
                timing@0 { /* fhd 60hz */
                    qcom,mdss-dsi-panel-phy-timings = [00 26 09 09 27 23 08 09 07 02 04 00 38 18];
                    qcom,display-topology = <1 0 1>,<2 2 1>;
                    qcom,default-topology-index = <1>;
                    //qcom,panel-roi-alignment=<540 30 540 30 540 30>;
                    };
                timing@1 { /* fhd 90hz */
                    qcom,mdss-dsi-panel-phy-timings = [00 26 09 09 27 23 08 09 07 02 04 00 38 18];
                    qcom,display-topology = <1 0 1>,<2 2 1>;
                    qcom,default-topology-index = <1>;
                    //qcom,panel-roi-alignment=<540 30 540 30 540 30>;
                    };
                };
};
